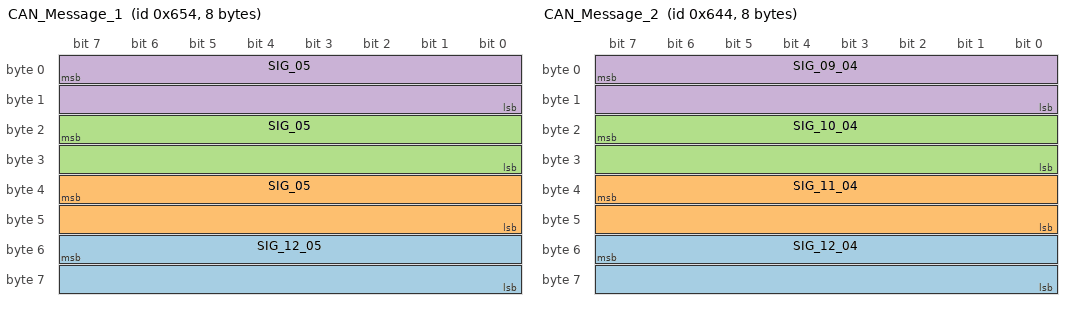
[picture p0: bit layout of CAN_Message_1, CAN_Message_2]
BO_ 1620 CAN_Message_1: 8 BCM
 SG_ SIG_12_05 : 55|16@0+ (0.001,0) [0|5] "V"  ECU,BCM
 SG_ SIG_05 : 39|16@0+ (0.001,0) [0|5] "V"  ECU,BCM
 SG_ SIG_05 : 23|16@0+ (0.001,0) [0|5] "V"  ECU,BCM
 SG_ SIG_05 : 7|16@0+ (0.001,0) [0|5] "V"  ECU,BCM

BO_ 1604 CAN_Message_2: 8 BCM
 SG_ SIG_12_04 : 55|16@0+ (0.001,0) [0|5] "V"  ECU,BCM
 SG_ SIG_11_04 : 39|16@0+ (0.001,0) [0|5] "V"  ECU,BCM
 SG_ SIG_10_04 : 23|16@0+ (0.001,0) [0|5] "V"  ECU,BCM
 SG_ SIG_09_04 : 7|16@0+ (0.001,0) [0|5] "V"  ECU,BCM

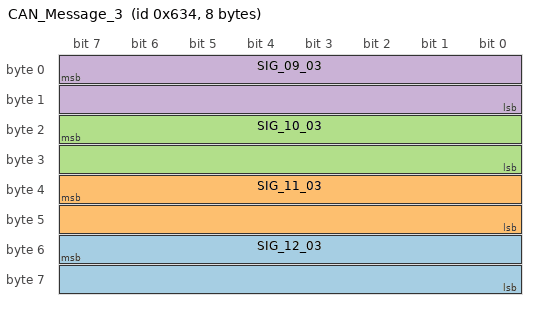
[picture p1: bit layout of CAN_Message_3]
BO_ 1588 CAN_Message_3: 8 BCM
 SG_ SIG_12_03 : 55|16@0+ (0.001,0) [0|5] "V"  ECU,BCM
 SG_ SIG_11_03 : 39|16@0+ (0.001,0) [0|5] "V"  ECU,BCM
 SG_ SIG_10_03 : 23|16@0+ (0.001,0) [0|5] "V"  ECU,BCM
 SG_ SIG_09_03 : 7|16@0+ (0.001,0) [0|5] "V"  ECU,BCM

CM_ SG_ 1770 CSCNT_DEV_10 "CMU_10 CSCNT_DEV";
CM_ SG_ 1770 CRRLTIN_YY_10 "CELL_08 CRRLTIN";
CM_ SG_ 1770 CELL_RSIST_YY_10 "CELL_yy INT_RESIST";
CM_ SG_ 1770 FRAME_NO_YY_10 "Automatic numbering table";
CM_ SG_ 1771 CSCNT_DEV_11 "CMU_11 CSCNT_DEV";
CM_ SG_ 1771 CRRLTIN_YY_11 "CELL_08 CRRLTIN";

BA_ "NBTMin" 10;
BA_ "NBTMax" 20;
BA_ "NWM-Knoten" BU_ TESTER 0;
BA_ "NWM-Knoten" BU_ TCU 1;
BA_ "DiagRequest" BO_ 1151 0;
BA_ "DiagState" BO_ 1151 0;
BA_ "FlexKomSigStartPos" SG_ 1589 BLC_DSTAT_HARN_03 0;
BA_ "FlexKomSigLaenge" SG_ 1589 BLC_DSTAT_HARN_03 1;

VAL_ 1770 CELL_RSIST_YY_10 65535 "SNA" ;
VAL_ 1770 FRAME_NO_YY_10 255 "SNA" ;
VAL_ 1771 CSCNT_DEV_11 65535 "SNA" ;
VAL_ 1771 CRRLTIN_YY_11 255 "SNA" ;
VAL_ 1697 NUM_TABLE_VALUE_10 15 "SIGNAL_DEFAULT" 14 "BATTERY_PACK_TYPE_14" 13 "BATTERY_PACK_TYPE_13" 12 "BATTERY_PACK_TYPE_12" 11 "BATTERY_PACK_TYPE_11" 10 "BATTERY_PACK_TYPE_10" 9 "BATTERY_PACK_TYPE_9" 8 "BATTERY_PACK_TYPE_8" 7 "BATTERY_PACK_TYPE_7" 6 "BATTERY_PACK_TYPE_6" 5 "BATTERY_PACK_TYPE_5" 4 "BATTERY_PACK_TYPE_4" 3 "BATTERY_PACK_TYPE_3" 2 "BATTERY_PACK_TYPE_2" 1 "BATTERY_PACK_TYPE_1" 0 "BATTERY_PACK_TYPE_0" ;

BU_: TCU TESTER SRS SAS PHEV OCM LDW_RLSM ETACS EPS ENG_PHEV ACCS_FCM ABS_ASC
BU_: TESTER TCU BMU2 CSM CMU_TEST CMU_12 CMU_11 CMU_10 CMU_09 CMU_08 CMU_07 CMU_06 CMU_05 CMU_04 CMU_03 CMU_02 CMU_01 CMU_00 BMU
